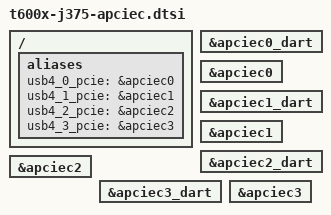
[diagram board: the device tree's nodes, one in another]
// SPDX-License-Identifier: GPL-2.0+ OR MIT
/*
 * Board part for the Mac Studio (j375c/j375d): USB4 ports 0-3 of die 0.
 * Included from t6001-j375c.dts and t6002-j375d.dts only: t600x-j375.dtsi
 * is shared with T602x boards, which have no APCIEC nodes.
 */

/ {
	aliases {
		/* used by m1n1 to fill the APCIEC tunables */
		usb4_0_pcie = &apciec0;
		usb4_1_pcie = &apciec1;
		usb4_2_pcie = &apciec2;
		usb4_3_pcie = &apciec3;
	};
};

&apciec0_dart {
	status = "okay";
};

&apciec0 {
	status = "okay";
};

&apciec1_dart {
	status = "okay";
};

&apciec1 {
	status = "okay";
};

&apciec2_dart {
	status = "okay";
};

&apciec2 {
	status = "okay";
};

&apciec3_dart {
	status = "okay";
};

&apciec3 {
	status = "okay";
};
